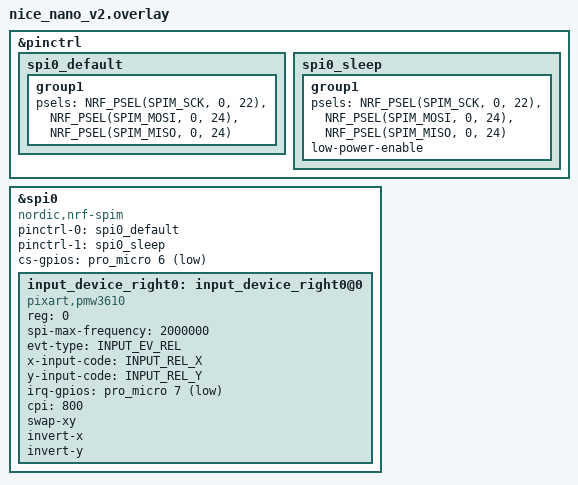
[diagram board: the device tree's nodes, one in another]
/**
 * Generated by Shield Wizard for ZMK
 * Applies to part "right" with controller "nice_nano_v2"
 */

// pin control for spi0
// - SCK on D4
// - MOSI on D5
// - MISO on D5
&pinctrl {
    /* configuration for spi0 device, default state */
    spi0_default: spi0_default {
        group1 {
            psels = <NRF_PSEL(SPIM_SCK, 0, 22)>,
                    <NRF_PSEL(SPIM_MOSI, 0, 24)>,
                    <NRF_PSEL(SPIM_MISO, 0, 24)>;
        };
    };
    /* configuration for spi0 device, sleep state */
    spi0_sleep: spi0_sleep {
        group1 {
            psels = <NRF_PSEL(SPIM_SCK, 0, 22)>,
                    <NRF_PSEL(SPIM_MOSI, 0, 24)>,
                    <NRF_PSEL(SPIM_MISO, 0, 24)>;
            low-power-enable;
        };
    };
};
&spi0 {
    compatible = "nordic,nrf-spim";
    status = "okay";
    pinctrl-0 = <&spi0_default>;
    pinctrl-1 = <&spi0_sleep>;
    pinctrl-names = "default", "sleep";
};

// devices on spi0

// CS pins for devices on spi0
&spi0 {
    cs-gpios = <&pro_micro 6 GPIO_ACTIVE_LOW>;
};

#include <zephyr/dt-bindings/input/input-event-codes.h>

&spi0 {
    input_device_right0: input_device_right0@0 {
        status = "okay";
        compatible = "pixart,pmw3610";
        reg = <0>;
        spi-max-frequency = <2000000>;
        evt-type = <INPUT_EV_REL>;
        x-input-code = <INPUT_REL_X>;
        y-input-code = <INPUT_REL_Y>;
        irq-gpios = <&pro_micro 7 (GPIO_ACTIVE_LOW | GPIO_PULL_UP)>;
        cpi = <800>;
        swap-xy;
        invert-x;
        invert-y;
    };
};
